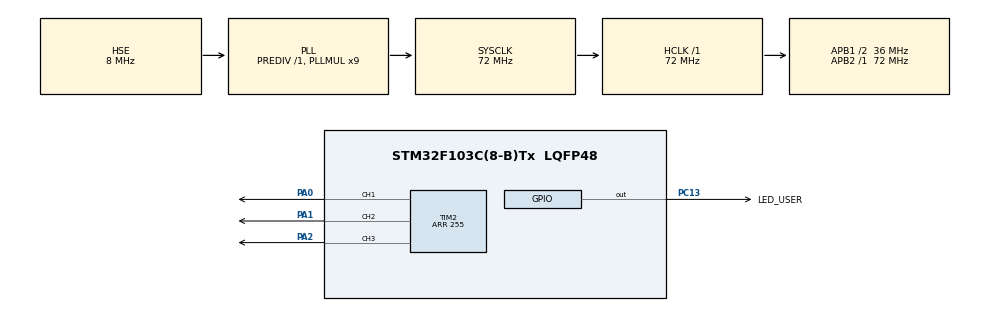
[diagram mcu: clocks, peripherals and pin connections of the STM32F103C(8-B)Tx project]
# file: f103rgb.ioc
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Dma.Request0=TIM2_CH1
Dma.Request1=TIM2_CH3
Dma.Request2=TIM2_CH2/CH4
Dma.TIM2_CH1.0.Direction=DMA_PERIPH_TO_MEMORY
Dma.TIM2_CH1.0.Instance=DMA1_Channel5
Dma.TIM2_CH1.0.MemDataAlignment=DMA_MDATAALIGN_HALFWORD
Dma.TIM2_CH1.0.MemInc=DMA_MINC_ENABLE
Dma.TIM2_CH1.0.Mode=DMA_NORMAL
Dma.TIM2_CH1.0.PeriphDataAlignment=DMA_PDATAALIGN_HALFWORD
Dma.TIM2_CH1.0.PeriphInc=DMA_PINC_DISABLE
Dma.TIM2_CH1.0.Priority=DMA_PRIORITY_LOW
Dma.TIM2_CH2/CH4.2.Direction=DMA_PERIPH_TO_MEMORY
Dma.TIM2_CH2/CH4.2.Instance=DMA1_Channel7
Dma.TIM2_CH2/CH4.2.MemDataAlignment=DMA_MDATAALIGN_HALFWORD
Dma.TIM2_CH2/CH4.2.MemInc=DMA_MINC_ENABLE
Dma.TIM2_CH2/CH4.2.Mode=DMA_NORMAL
Dma.TIM2_CH2/CH4.2.PeriphDataAlignment=DMA_PDATAALIGN_HALFWORD
Dma.TIM2_CH2/CH4.2.PeriphInc=DMA_PINC_DISABLE
Dma.TIM2_CH2/CH4.2.Priority=DMA_PRIORITY_LOW
Dma.TIM2_CH3.1.Direction=DMA_PERIPH_TO_MEMORY
Dma.TIM2_CH3.1.Instance=DMA1_Channel1
Dma.TIM2_CH3.1.MemDataAlignment=DMA_MDATAALIGN_HALFWORD
Dma.TIM2_CH3.1.MemInc=DMA_MINC_ENABLE
Dma.TIM2_CH3.1.Mode=DMA_NORMAL
Dma.TIM2_CH3.1.PeriphDataAlignment=DMA_PDATAALIGN_HALFWORD
Dma.TIM2_CH3.1.PeriphInc=DMA_PINC_DISABLE
Dma.TIM2_CH3.1.Priority=DMA_PRIORITY_LOW
Mcu.Family=STM32F1
Mcu.Name=STM32F103C(8-B)Tx
Mcu.Package=LQFP48
NVIC.DMA1_Channel1_IRQn=true\:0\:0\:false\:false\:true\:false\:true\:true
NVIC.DMA1_Channel5_IRQn=true\:0\:0\:false\:false\:true\:false\:true\:true
NVIC.DMA1_Channel7_IRQn=true\:0\:0\:false\:false\:true\:false\:true\:true
NVIC.PriorityGroup=NVIC_PRIORITYGROUP_4
PA0-WKUP.GPIO_Speed=GPIO_SPEED_FREQ_HIGH
PA0-WKUP.Signal=S_TIM2_CH1_ETR
PA1.GPIO_Speed=GPIO_SPEED_FREQ_HIGH
PA1.Signal=S_TIM2_CH2
PA13.Mode=Serial_Wire
PA13.Signal=SYS_JTMS-SWDIO
PA14.Mode=Serial_Wire
PA14.Signal=SYS_JTCK-SWCLK
PA2.GPIO_Speed=GPIO_SPEED_FREQ_HIGH
PA2.Signal=S_TIM2_CH3
PC13-TAMPER-RTC.GPIO_Label=LED_USER
PC13-TAMPER-RTC.Signal=GPIO_Output
PD0-OSC_IN.Mode=HSE-External-Oscillator
PD0-OSC_IN.Signal=RCC_OSC_IN
PD1-OSC_OUT.Mode=HSE-External-Oscillator
PD1-OSC_OUT.Signal=RCC_OSC_OUT
ProjectManager.HeapSize=0x200
ProjectManager.StackSize=0x400
ProjectManager.TargetToolchain=STM32CubeIDE
RCC.AHBFreq_Value=72000000
RCC.APB1CLKDivider=RCC_HCLK_DIV2
RCC.APB1Freq_Value=36000000
RCC.APB1TimFreq_Value=72000000
RCC.APB2Freq_Value=72000000
RCC.APB2TimFreq_Value=72000000
RCC.HCLKFreq_Value=72000000
RCC.PLLMUL=RCC_PLL_MUL9
RCC.PLLSourceVirtual=RCC_PLLSOURCE_HSE
RCC.SYSCLKFreq_VALUE=72000000
RCC.SYSCLKSource=RCC_SYSCLKSOURCE_PLLCLK
RCC.USBFreq_Value=72000000
SH.S_TIM2_CH1_ETR.0=TIM2_CH1,PWM Generation1 CH1
SH.S_TIM2_CH2.0=TIM2_CH2,PWM Generation2 CH2
SH.S_TIM2_CH3.0=TIM2_CH3,PWM Generation3 CH3
TIM2.Channel-PWM\ Generation1\ CH1=TIM_CHANNEL_1
TIM2.Channel-PWM\ Generation2\ CH2=TIM_CHANNEL_2
TIM2.Channel-PWM\ Generation3\ CH3=TIM_CHANNEL_3
TIM2.Period=255
board=custom

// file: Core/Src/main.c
/* USER CODE BEGIN Header */
/**
  ******************************************************************************
  * @file           : main.c
  * @brief          : Main program body
  ******************************************************************************
  * @attention
  *
  * Copyright (c) 2024 STMicroelectronics.
  * All rights reserved.
  *
  * This software is licensed under terms that can be found in the LICENSE file
  * in the root directory of this software component.
  * If no LICENSE file comes with this software, it is provided AS-IS.
  *
  ******************************************************************************
  */
/* USER CODE END Header */
#include "main.h"

TIM_HandleTypeDef htim2;
DMA_HandleTypeDef hdma_tim2_ch1;
DMA_HandleTypeDef hdma_tim2_ch3;
DMA_HandleTypeDef hdma_tim2_ch2_ch4;

void SystemClock_Config(void);
static void MX_GPIO_Init(void);
static void MX_DMA_Init(void);
static void MX_TIM2_Init(void);

/* USER CODE BEGIN 0 */
void SetRGB(uint8_t red, uint8_t green, uint8_t blue)
{
  __HAL_TIM_SET_COMPARE(&htim2, TIM_CHANNEL_1, red);
  __HAL_TIM_SET_COMPARE(&htim2, TIM_CHANNEL_2, green);
  __HAL_TIM_SET_COMPARE(&htim2, TIM_CHANNEL_3, blue);
}
/* USER CODE END 0 */

int main(void)
{

  /* MCU Configuration--------------------------------------------------------*/

  /* Reset of all peripherals, Initializes the Flash interface and the Systick. */
  HAL_Init();

  /* Configure the system clock */
  SystemClock_Config();

  /* Initialize all configured peripherals */
  MX_GPIO_Init();
  MX_DMA_Init();
  MX_TIM2_Init();
  /* USER CODE BEGIN 2 */
  HAL_TIM_PWM_Start(&htim2, TIM_CHANNEL_1); // Assuming PB0 is on TIM2_CH1
   HAL_TIM_PWM_Start(&htim2, TIM_CHANNEL_2); // Assuming PB1 is on TIM2_CH2
   HAL_TIM_PWM_Start(&htim2, TIM_CHANNEL_3); // Assuming PB2 is on TIM2_CH3
   uint32_t val;
   HAL_GPIO_WritePin(LED_USER_GPIO_Port, LED_USER_Pin, GPIO_PIN_RESET);

  /* USER CODE END 2 */

  /* Infinite loop */
  while (1)
  {
	   /* for (val = 255; val > 0; val--)
	    {
	      __HAL_TIM_SET_COMPARE(&htim2, TIM_CHANNEL_1, val);
	      __HAL_TIM_SET_COMPARE(&htim2, TIM_CHANNEL_2, 255 - val);
	      __HAL_TIM_SET_COMPARE(&htim2, TIM_CHANNEL_3, 128 - val);
	      HAL_Delay(5);
	    }
	    for (val = 0; val < 255; val++)
	    {
	      __HAL_TIM_SET_COMPARE(&htim2, TIM_CHANNEL_1, val);
	      __HAL_TIM_SET_COMPARE(&htim2, TIM_CHANNEL_2, 255 - val);
	      __HAL_TIM_SET_COMPARE(&htim2, TIM_CHANNEL_3, 128 - val);
	      HAL_Delay(5);}*/

	    SetRGB(255, 0, 0); // ตัวอย่าง: สีแดง
	    HAL_Delay(1000);
	    SetRGB(0, 255, 0); // ตัวอย่าง: สีเขียว
	    HAL_Delay(1000);
	    SetRGB(0, 0, 255); // ตัวอย่าง: สีน้ำเงิน
	    HAL_Delay(1000);
  }
}

void SystemClock_Config(void)
{
  RCC_OscInitTypeDef RCC_OscInitStruct = {0};
  RCC_ClkInitTypeDef RCC_ClkInitStruct = {0};

  /** Initializes the RCC Oscillators according to the specified parameters
  * in the RCC_OscInitTypeDef structure.
  */
  RCC_OscInitStruct.OscillatorType = RCC_OSCILLATORTYPE_HSE;
  RCC_OscInitStruct.HSEState = RCC_HSE_ON;
  RCC_OscInitStruct.HSEPredivValue = RCC_HSE_PREDIV_DIV1;
  RCC_OscInitStruct.HSIState = RCC_HSI_ON;
  RCC_OscInitStruct.PLL.PLLState = RCC_PLL_ON;
  RCC_OscInitStruct.PLL.PLLSource = RCC_PLLSOURCE_HSE;
  RCC_OscInitStruct.PLL.PLLMUL = RCC_PLL_MUL9;
  if (HAL_RCC_OscConfig(&RCC_OscInitStruct) != HAL_OK)
  {
    Error_Handler();
  }

  /** Initializes the CPU, AHB and APB buses clocks
  */
  RCC_ClkInitStruct.ClockType = RCC_CLOCKTYPE_HCLK|RCC_CLOCKTYPE_SYSCLK
                              |RCC_CLOCKTYPE_PCLK1|RCC_CLOCKTYPE_PCLK2;
  RCC_ClkInitStruct.SYSCLKSource = RCC_SYSCLKSOURCE_PLLCLK;
  RCC_ClkInitStruct.AHBCLKDivider = RCC_SYSCLK_DIV1;
  RCC_ClkInitStruct.APB1CLKDivider = RCC_HCLK_DIV2;
  RCC_ClkInitStruct.APB2CLKDivider = RCC_HCLK_DIV1;

  if (HAL_RCC_ClockConfig(&RCC_ClkInitStruct, FLASH_LATENCY_2) != HAL_OK)
  {
    Error_Handler();
  }
}

static void MX_TIM2_Init(void)
{

  TIM_MasterConfigTypeDef sMasterConfig = {0};
  TIM_OC_InitTypeDef sConfigOC = {0};

  htim2.Instance = TIM2;
  htim2.Init.Prescaler = 0;
  htim2.Init.CounterMode = TIM_COUNTERMODE_UP;
  htim2.Init.Period = 255;
  htim2.Init.ClockDivision = TIM_CLOCKDIVISION_DIV1;
  htim2.Init.AutoReloadPreload = TIM_AUTORELOAD_PRELOAD_DISABLE;
  if (HAL_TIM_PWM_Init(&htim2) != HAL_OK)
  {
    Error_Handler();
  }
  sMasterConfig.MasterOutputTrigger = TIM_TRGO_RESET;
  sMasterConfig.MasterSlaveMode = TIM_MASTERSLAVEMODE_DISABLE;
  if (HAL_TIMEx_MasterConfigSynchronization(&htim2, &sMasterConfig) != HAL_OK)
  {
    Error_Handler();
  }
  sConfigOC.OCMode = TIM_OCMODE_PWM1;
  sConfigOC.Pulse = 0;
  sConfigOC.OCPolarity = TIM_OCPOLARITY_HIGH;
  sConfigOC.OCFastMode = TIM_OCFAST_DISABLE;
  if (HAL_TIM_PWM_ConfigChannel(&htim2, &sConfigOC, TIM_CHANNEL_1) != HAL_OK)
  {
    Error_Handler();
  }
  if (HAL_TIM_PWM_ConfigChannel(&htim2, &sConfigOC, TIM_CHANNEL_2) != HAL_OK)
  {
    Error_Handler();
  }
  if (HAL_TIM_PWM_ConfigChannel(&htim2, &sConfigOC, TIM_CHANNEL_3) != HAL_OK)
  {
    Error_Handler();
  }
  HAL_TIM_MspPostInit(&htim2);

}

static void MX_DMA_Init(void)
{

  /* DMA controller clock enable */
  __HAL_RCC_DMA1_CLK_ENABLE();

  /* DMA interrupt init */
  /* DMA1_Channel1_IRQn interrupt configuration */
  HAL_NVIC_SetPriority(DMA1_Channel1_IRQn, 0, 0);
  HAL_NVIC_EnableIRQ(DMA1_Channel1_IRQn);
  /* DMA1_Channel5_IRQn interrupt configuration */
  HAL_NVIC_SetPriority(DMA1_Channel5_IRQn, 0, 0);
  HAL_NVIC_EnableIRQ(DMA1_Channel5_IRQn);
  /* DMA1_Channel7_IRQn interrupt configuration */
  HAL_NVIC_SetPriority(DMA1_Channel7_IRQn, 0, 0);
  HAL_NVIC_EnableIRQ(DMA1_Channel7_IRQn);

}

static void MX_GPIO_Init(void)
{
  GPIO_InitTypeDef GPIO_InitStruct = {0};

  /* GPIO Ports Clock Enable */
  __HAL_RCC_GPIOC_CLK_ENABLE();
  __HAL_RCC_GPIOD_CLK_ENABLE();
  __HAL_RCC_GPIOA_CLK_ENABLE();

  /*Configure GPIO pin Output Level */
  HAL_GPIO_WritePin(LED_USER_GPIO_Port, LED_USER_Pin, GPIO_PIN_RESET);

  /*Configure GPIO pin : LED_USER_Pin */
  GPIO_InitStruct.Pin = LED_USER_Pin;
  GPIO_InitStruct.Mode = GPIO_MODE_OUTPUT_PP;
  GPIO_InitStruct.Pull = GPIO_NOPULL;
  GPIO_InitStruct.Speed = GPIO_SPEED_FREQ_LOW;
  HAL_GPIO_Init(LED_USER_GPIO_Port, &GPIO_InitStruct);

}

void Error_Handler(void)
{
  __disable_irq();
  while (1)
  {
  }
}
